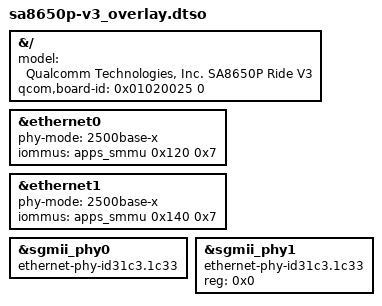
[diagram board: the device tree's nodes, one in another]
// SPDX-License-Identifier: BSD-3-Clause
/*
 * Copyright (c) 2024-2025 Qualcomm Innovation Center, Inc. All rights reserved.
 */

#include "sa8650p_overlay.dtso"

&{/} {
	model = "Qualcomm Technologies, Inc. SA8650P Ride V3";
	qcom,board-id = <0x01020025 0>;
};

&ethernet0 {
	phy-mode = "2500base-x";
	iommus = <&apps_smmu 0x120 0x7>;
};

&ethernet1 {
	phy-mode = "2500base-x";
	iommus = <&apps_smmu 0x140 0x7>;
};

&sgmii_phy0 {
	compatible = "ethernet-phy-id31c3.1c33";
};

&sgmii_phy1 {
	compatible = "ethernet-phy-id31c3.1c33";
	reg = <0x0>;
};

